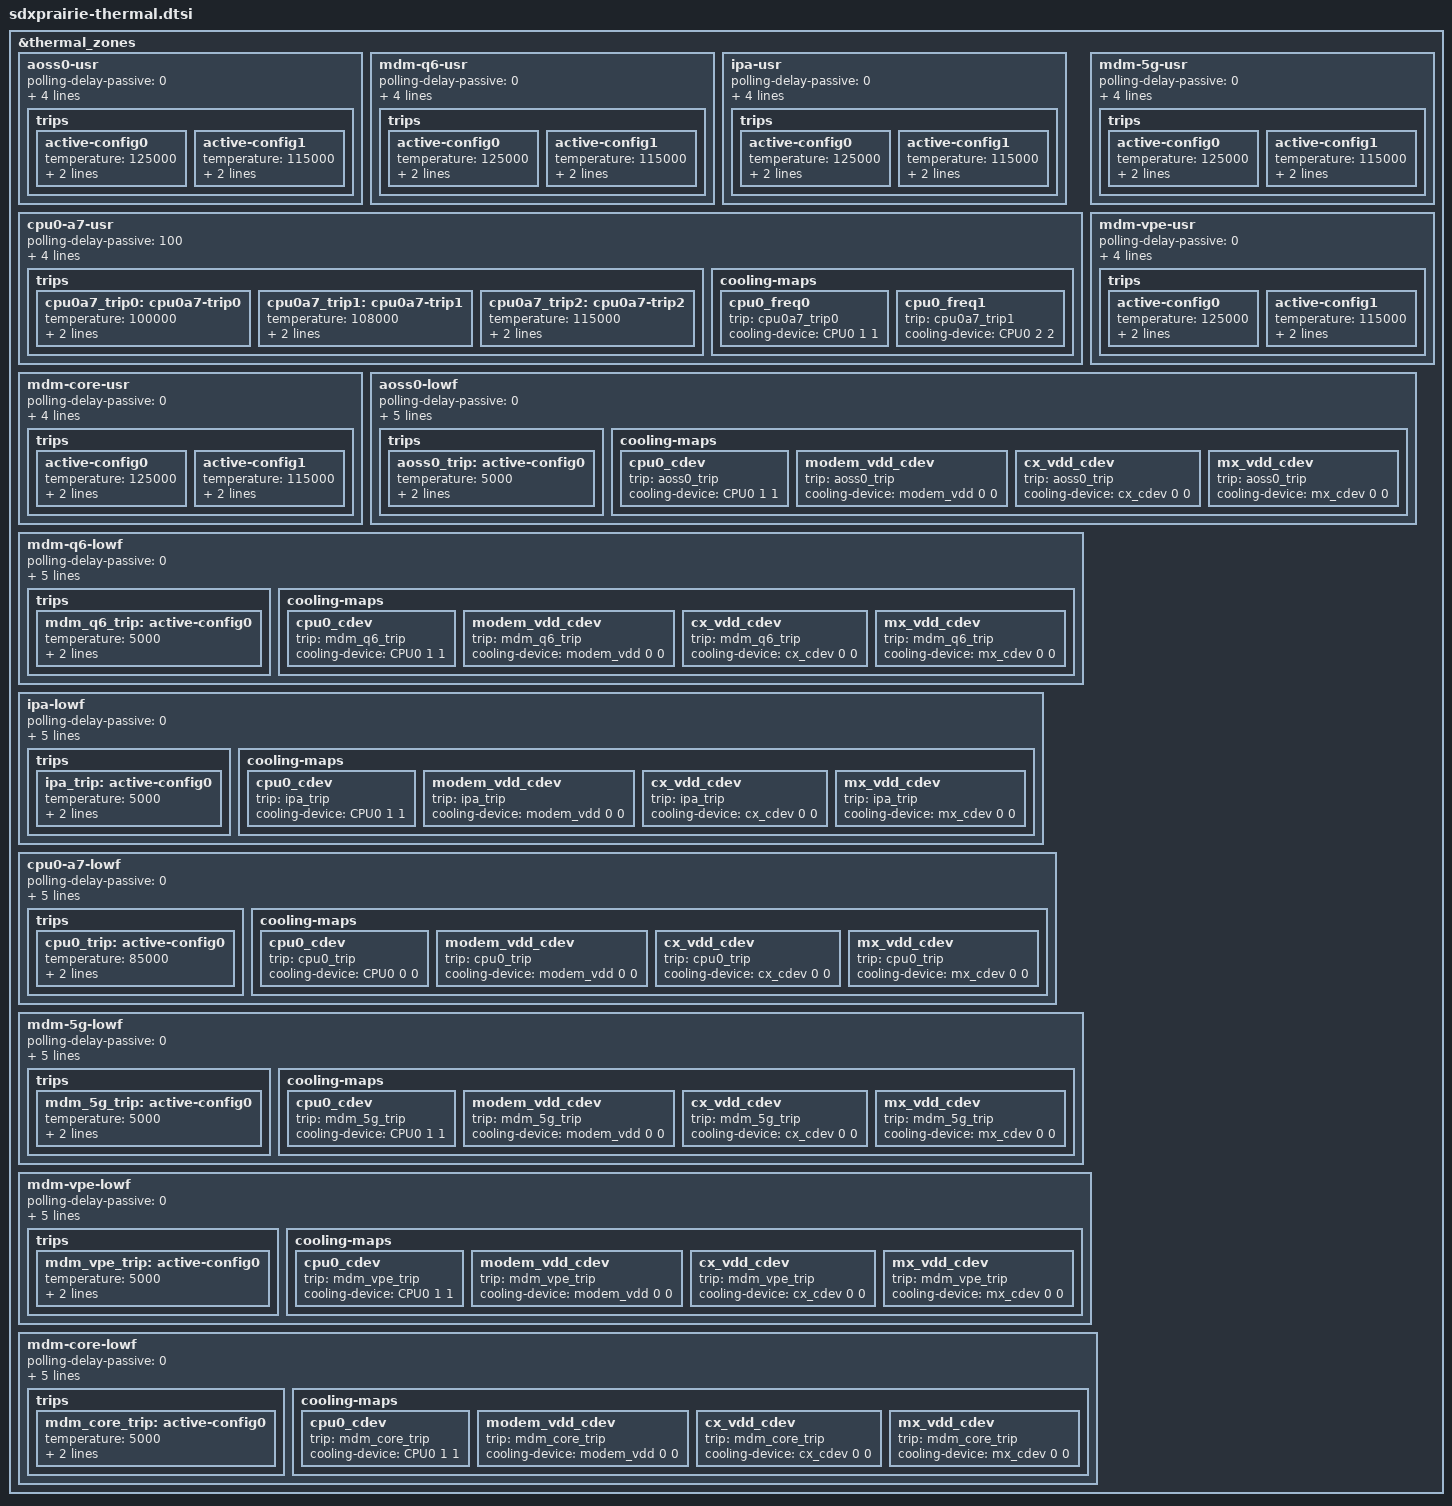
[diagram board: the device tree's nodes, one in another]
/* Copyright (c) 2019-2020, The Linux Foundation. All rights reserved.
 *
 * This program is free software; you can redistribute it and/or modify
 * it under the terms of the GNU General Public License version 2 and
 * only version 2 as published by the Free Software Foundation.
 *
 * This program is distributed in the hope that it will be useful,
 * but WITHOUT ANY WARRANTY; without even the implied warranty of
 * MERCHANTABILITY or FITNESS FOR A PARTICULAR PURPOSE.  See the
 * GNU General Public License for more details.
 */

#include <dt-bindings/thermal/thermal.h>
#include "sdxprairie-thermal-common.dtsi"

&thermal_zones {
	aoss0-usr {
		polling-delay-passive = <0>;
		polling-delay = <0>;
		thermal-governor = "user_space";
		thermal-sensors = <&tsens0 0>;
		wake-capable-sensor;
		trips {
			active-config0 {
				temperature = <125000>;
				hysteresis = <1000>;
				type = "passive";
			};
			active-config1 {
				temperature = <115000>;
				hysteresis = <5000>;
				type = "passive";
			};
		};
	};

	mdm-q6-usr {
		polling-delay-passive = <0>;
		polling-delay = <0>;
		thermal-governor = "user_space";
		thermal-sensors = <&tsens0 1>;
		wake-capable-sensor;
		trips {
			active-config0 {
				temperature = <125000>;
				hysteresis = <1000>;
				type = "passive";
			};
			active-config1 {
				temperature = <115000>;
				hysteresis = <5000>;
				type = "passive";
			};
		};
	};

	ipa-usr {
		polling-delay-passive = <0>;
		polling-delay = <0>;
		thermal-governor = "user_space";
		thermal-sensors = <&tsens0 2>;
		wake-capable-sensor;
		trips {
			active-config0 {
				temperature = <125000>;
				hysteresis = <1000>;
				type = "passive";
			};
			active-config1 {
				temperature = <115000>;
				hysteresis = <5000>;
				type = "passive";
			};
		};
	};

	cpu0-a7-usr {
		polling-delay-passive = <100>;
		polling-delay = <10>;
		thermal-governor = "step_wise";
		thermal-sensors = <&tsens0 3>;
		wake-capable-sensor;
		trips {
			cpu0a7_trip0: cpu0a7-trip0 {
				temperature = <100000>;
				hysteresis = <15000>;
				type = "passive";
			};
			cpu0a7_trip1: cpu0a7-trip1 {
				temperature = <108000>;
				hysteresis = <15000>;
				type = "passive";
			};
			cpu0a7_trip2: cpu0a7-trip2 {
				temperature = <115000>;
				hysteresis = <10000>;
				type = "passive";
			};
		};
		cooling-maps {
			cpu0_freq0 {
				trip = <&cpu0a7_trip0>;
				cooling-device = <&CPU0 1 1>;
			};
			cpu0_freq1 {
				trip = <&cpu0a7_trip1>;
				cooling-device = <&CPU0 2 2>;
			};
		};
	};

	mdm-5g-usr {
		polling-delay-passive = <0>;
		polling-delay = <0>;
		thermal-sensors = <&tsens0 4>;
		thermal-governor = "user_space";
		wake-capable-sensor;
		trips {
			active-config0 {
				temperature = <125000>;
				hysteresis = <1000>;
				type = "passive";
			};
			active-config1 {
				temperature = <115000>;
				hysteresis = <5000>;
				type = "passive";
			};
		};
	};

	mdm-vpe-usr {
		polling-delay-passive = <0>;
		polling-delay = <0>;
		thermal-sensors = <&tsens0 5>;
		thermal-governor = "user_space";
		wake-capable-sensor;
		trips {
			active-config0 {
				temperature = <125000>;
				hysteresis = <1000>;
				type = "passive";
			};
			active-config1 {
				temperature = <115000>;
				hysteresis = <5000>;
				type = "passive";
			};
		};
	};

	mdm-core-usr {
		polling-delay-passive = <0>;
		polling-delay = <0>;
		thermal-sensors = <&tsens0 6>;
		thermal-governor = "user_space";
		wake-capable-sensor;
		trips {
			active-config0 {
				temperature = <125000>;
				hysteresis = <1000>;
				type = "passive";
			};
			active-config1 {
				temperature = <115000>;
				hysteresis = <5000>;
				type = "passive";
			};
		};
	};

	aoss0-lowf {
		polling-delay-passive = <0>;
		polling-delay = <0>;
		thermal-governor = "low_limits_floor";
		thermal-sensors = <&tsens0 0>;
		wake-capable-sensor;
		tracks-low;
		trips {
			aoss0_trip: active-config0 {
				temperature = <5000>;
				hysteresis = <5000>;
				type = "passive";
			};
		};
		cooling-maps {
			cpu0_cdev {
				trip = <&aoss0_trip>;
				cooling-device = <&CPU0 1 1>;
			};
			modem_vdd_cdev {
				trip = <&aoss0_trip>;
				cooling-device = <&modem_vdd 0 0>;
			};
			cx_vdd_cdev {
				trip = <&aoss0_trip>;
				cooling-device = <&cx_cdev 0 0>;
			};
			mx_vdd_cdev {
				trip = <&aoss0_trip>;
				cooling-device = <&mx_cdev 0 0>;
			};
		};
	};

	mdm-q6-lowf {
		polling-delay-passive = <0>;
		polling-delay = <0>;
		thermal-governor = "low_limits_floor";
		thermal-sensors = <&tsens0 1>;
		wake-capable-sensor;
		tracks-low;
		trips {
			mdm_q6_trip: active-config0 {
				temperature = <5000>;
				hysteresis = <5000>;
				type = "passive";
			};
		};
		cooling-maps {
			cpu0_cdev {
				trip = <&mdm_q6_trip>;
				cooling-device = <&CPU0 1 1>;
			};
			modem_vdd_cdev {
				trip = <&mdm_q6_trip>;
				cooling-device = <&modem_vdd 0 0>;
			};
			cx_vdd_cdev {
				trip = <&mdm_q6_trip>;
				cooling-device = <&cx_cdev 0 0>;
			};
			mx_vdd_cdev {
				trip = <&mdm_q6_trip>;
				cooling-device = <&mx_cdev 0 0>;
			};
		};
	};

	ipa-lowf {
		polling-delay-passive = <0>;
		polling-delay = <0>;
		thermal-governor = "low_limits_floor";
		thermal-sensors = <&tsens0 2>;
		wake-capable-sensor;
		tracks-low;
		trips {
			ipa_trip: active-config0 {
				temperature = <5000>;
				hysteresis = <5000>;
				type = "passive";
			};
		};
		cooling-maps {
			cpu0_cdev {
				trip = <&ipa_trip>;
				cooling-device = <&CPU0 1 1>;
			};
			modem_vdd_cdev {
				trip = <&ipa_trip>;
				cooling-device = <&modem_vdd 0 0>;
			};
			cx_vdd_cdev {
				trip = <&ipa_trip>;
				cooling-device = <&cx_cdev 0 0>;
			};
			mx_vdd_cdev {
				trip = <&ipa_trip>;
				cooling-device = <&mx_cdev 0 0>;
			};
		};
	};

	cpu0-a7-lowf {
		polling-delay-passive = <0>;
		polling-delay = <0>;
		thermal-governor = "low_limits_floor";
		thermal-sensors = <&tsens0 3>;
		wake-capable-sensor;
		tracks-low;
		trips {
			cpu0_trip: active-config0 {
				temperature = <85000>;
				hysteresis = <5000>;
				type = "passive";
			};
		};
		cooling-maps {
			cpu0_cdev {
				trip = <&cpu0_trip>;
				cooling-device = <&CPU0 0 0>;
			};
			modem_vdd_cdev {
				trip = <&cpu0_trip>;
				cooling-device = <&modem_vdd 0 0>;
			};
			cx_vdd_cdev {
				trip = <&cpu0_trip>;
				cooling-device = <&cx_cdev 0 0>;
			};
			mx_vdd_cdev {
				trip = <&cpu0_trip>;
				cooling-device = <&mx_cdev 0 0>;
			};
		};
	};

	mdm-5g-lowf {
		polling-delay-passive = <0>;
		polling-delay = <0>;
		thermal-sensors = <&tsens0 4>;
		thermal-governor = "low_limits_floor";
		wake-capable-sensor;
		tracks-low;
		trips {
			mdm_5g_trip: active-config0 {
				temperature = <5000>;
				hysteresis = <5000>;
				type = "passive";
			};
		};
		cooling-maps {
			cpu0_cdev {
				trip = <&mdm_5g_trip>;
				cooling-device = <&CPU0 1 1>;
			};
			modem_vdd_cdev {
				trip = <&mdm_5g_trip>;
				cooling-device = <&modem_vdd 0 0>;
			};
			cx_vdd_cdev {
				trip = <&mdm_5g_trip>;
				cooling-device = <&cx_cdev 0 0>;
			};
			mx_vdd_cdev {
				trip = <&mdm_5g_trip>;
				cooling-device = <&mx_cdev 0 0>;
			};
		};
	};

	mdm-vpe-lowf {
		polling-delay-passive = <0>;
		polling-delay = <0>;
		thermal-sensors = <&tsens0 5>;
		thermal-governor = "low_limits_floor";
		wake-capable-sensor;
		tracks-low;
		trips {
			mdm_vpe_trip: active-config0 {
				temperature = <5000>;
				hysteresis = <5000>;
				type = "passive";
			};
		};
		cooling-maps {
			cpu0_cdev {
				trip = <&mdm_vpe_trip>;
				cooling-device = <&CPU0 1 1>;
			};
			modem_vdd_cdev {
				trip = <&mdm_vpe_trip>;
				cooling-device = <&modem_vdd 0 0>;
			};
			cx_vdd_cdev {
				trip = <&mdm_vpe_trip>;
				cooling-device = <&cx_cdev 0 0>;
			};
			mx_vdd_cdev {
				trip = <&mdm_vpe_trip>;
				cooling-device = <&mx_cdev 0 0>;
			};
		};
	};

	mdm-core-lowf {
		polling-delay-passive = <0>;
		polling-delay = <0>;
		thermal-sensors = <&tsens0 6>;
		thermal-governor = "low_limits_floor";
		wake-capable-sensor;
		tracks-low;
		trips {
			mdm_core_trip: active-config0 {
				temperature = <5000>;
				hysteresis = <5000>;
				type = "passive";
			};
		};
		cooling-maps {
			cpu0_cdev {
				trip = <&mdm_core_trip>;
				cooling-device = <&CPU0 1 1>;
			};
			modem_vdd_cdev {
				trip = <&mdm_core_trip>;
				cooling-device = <&modem_vdd 0 0>;
			};
			cx_vdd_cdev {
				trip = <&mdm_core_trip>;
				cooling-device = <&cx_cdev 0 0>;
			};
			mx_vdd_cdev {
				trip = <&mdm_core_trip>;
				cooling-device = <&mx_cdev 0 0>;
			};
		};
	};
};
